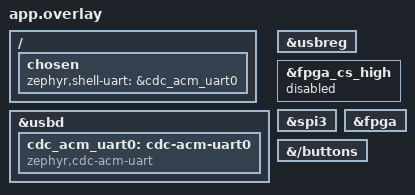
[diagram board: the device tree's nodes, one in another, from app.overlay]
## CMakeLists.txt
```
# SPDX-License-Identifier: Apache-2.0

cmake_minimum_required(VERSION 3.20.0)
list(APPEND BOARD_ROOT "${CMAKE_CURRENT_SOURCE_DIR}/..")
list(APPEND DTS_ROOT "${CMAKE_CURRENT_SOURCE_DIR}/..")
find_package(Zephyr REQUIRED HINTS $ENV{ZEPHYR_BASE})
project(bridge_fpga_dev)

set(VME_FILE "${CMAKE_CURRENT_SOURCE_DIR}/bridge-hello.vme" CACHE FILEPATH "Reviewed Full VME input")
set(VME_HEADER "${CMAKE_CURRENT_BINARY_DIR}/vme_image.h")
add_custom_command(OUTPUT ${VME_HEADER}
  COMMAND ${PYTHON_EXECUTABLE} ${CMAKE_CURRENT_SOURCE_DIR}/tools/embed_vme.py
          ${VME_FILE} ${CMAKE_CURRENT_SOURCE_DIR}/reviewed-vme.sha256 ${VME_HEADER}
  DEPENDS ${VME_FILE} reviewed-vme.sha256 tools/embed_vme.py
  VERBATIM)
target_include_directories(app PRIVATE ${CMAKE_CURRENT_BINARY_DIR})
target_sources(app PRIVATE src/main.c src/vme.c src/jtag.c src/fpga_gpio.c src/fpga_spi.c ${VME_HEADER})
```

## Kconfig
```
mainmenu "Bridge FPGA programmer"

config FPGA_FLASH_WRITE
	bool "Allow explicitly requested FPGA Flash programming"
	default n
	help
	  Enable only after approval of the reviewed VME operation sequence.
	  Programming still requires the explicit USB shell command.

source "Kconfig.zephyr"
```

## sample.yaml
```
sample:
  name: Bridge MachXO2 JTAG programmer
tests:
  sample.bridge.fpga:
    platform_allow: bridge/nrf5340/cpuapp
    integration_platforms:
      - bridge/nrf5340/cpuapp
    build_only: true
    tags:
      - gpio
      - usb
```

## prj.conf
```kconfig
CONFIG_USB_DEVICE_STACK=y
CONFIG_USB_DEVICE_PRODUCT="SenseLab Bridge FPGA Dev"
CONFIG_USB_DEVICE_PID=0x0001
CONFIG_LOG=y
CONFIG_USB_DRIVER_LOG_LEVEL_ERR=y
CONFIG_USB_DEVICE_LOG_LEVEL_ERR=y
CONFIG_SERIAL=y
CONFIG_UART_INTERRUPT_DRIVEN=y
CONFIG_UART_LINE_CTRL=y
CONFIG_USB_DEVICE_INITIALIZE_AT_BOOT=n

# Shared Bridge board GPIOs and FPGA runtime SPI transport.
CONFIG_GPIO=y
CONFIG_GPIO_HOGS=y
CONFIG_SPI=y
CONFIG_TIMING_FUNCTIONS=y
# Use Nordic TIMER2 so elapsed time includes CPU sleep during the SPI wait.
CONFIG_CORTEX_M_DWT=n
CONFIG_SHELL=y
CONFIG_SHELL_BACKEND_SERIAL=y
# Allow pasted shell commands in one USB burst.
CONFIG_SHELL_BACKEND_SERIAL_RX_RING_BUFFER_SIZE=512
CONFIG_SHELL_STACK_SIZE=8192
CONFIG_HEAP_MEM_POOL_SIZE=65536
CONFIG_MAIN_STACK_SIZE=2048
CONFIG_FPGA_FLASH_WRITE=y
```

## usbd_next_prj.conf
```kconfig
CONFIG_USB_DEVICE_STACK_NEXT=y

CONFIG_SERIAL=y
CONFIG_UART_LINE_CTRL=y
CONFIG_USBD_CDC_ACM_CLASS=y

CONFIG_LOG=y
CONFIG_USBD_LOG_LEVEL_WRN=y
CONFIG_UDC_DRIVER_LOG_LEVEL_WRN=y
CONFIG_USBD_CDC_ACM_LOG_LEVEL_ERR=y

CONFIG_SAMPLE_USBD_PID=0x0001
CONFIG_SAMPLE_USBD_PRODUCT="USBD CDC ACM sample"
```

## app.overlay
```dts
/*
 * Copyright (c) 2021 Nordic Semiconductor ASA
 *
 * SPDX-License-Identifier: Apache-2.0
 */

/* Native USB command and diagnostic shell. */
/ {
	chosen { zephyr,shell-uart = &cdc_acm_uart0; };
};
zephyr_udc0: &usbd {
	status = "okay";
	cdc_acm_uart0: cdc-acm-uart0 {
		compatible = "zephyr,cdc-acm-uart";
	};
};

&usbreg { status = "okay"; };

/* SPI3 owns FPGA_CS_N; storage chip selects retain their boot holds. */
&fpga_cs_high { status = "disabled"; };
&spi3 { status = "okay"; };
&fpga { status = "okay"; };

/* Expose BTN_A/BTN_B without input handlers or application actions. */
&{/buttons} { status = "okay"; };
```

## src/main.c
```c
#include <zephyr/kernel.h>
#include <zephyr/drivers/gpio.h>
#include <zephyr/shell/shell.h>
#include <zephyr/usb/usb_device.h>
#include <string.h>
#include "fpga_gpio.h"
#include "jtag.h"
#include "vme_image.h"

static const struct shell *active_shell;
void fpga_message(const char *text)
{
	shell_fprintf(active_shell, SHELL_NORMAL, "%s", text);
}
static int identify(const struct shell *sh)
{
	active_shell = sh;
	int result = fpga_gpio_init();
	uint32_t id = 0;
	if (!result) result = jtag_identify(&fpga_io, &id);
	shell_print(sh, "IDCODE=%08x expected=012b8043 chain-test=%s result=%d DONE=%d",
		    id, result ? "FAIL" : "PASS", result, result ? -1 : fpga_done());
	return result;
}
static int cmd_id(const struct shell *sh, size_t argc, char **argv)
{
	return identify(sh);
}
static int cmd_info(const struct shell *sh, size_t argc, char **argv)
{
	shell_print(sh, "Full VME 12.1, %u bytes, SHA256=%s", (unsigned)sizeof(vme_image), VME_SHA256);
	shell_print(sh, "CRC check=%d; Flash-write support=%s", vme_check(vme_image, sizeof(vme_image)),
		    IS_ENABLED(CONFIG_FPGA_FLASH_WRITE) ? "enabled" : "disabled");
	shell_print(sh, "Sequence includes SRAM/CF/UFM/Feature erase, 575 page writes, USERCODE,");
	shell_print(sh, "Feature Row=0000000000000000, FEABITS=0x0620, verify, DONE and ISC_DISABLE.");
	shell_print(sh, "No OTP/security opcodes. Application behavior is not proven by verification.");
	return 0;
}
static int cmd_program(const struct shell *sh, size_t argc, char **argv)
{
	if (!IS_ENABLED(CONFIG_FPGA_FLASH_WRITE)) {
		shell_error(sh, "Flash writes disabled in this build; first-write approval is required.");
		return -EACCES;
	}
	if (strcmp(argv[1], VME_SHA256)) {
		shell_error(sh, "Supply the full SHA256 printed by fpga info to confirm this exact image.");
		return -EINVAL;
	}
	int result = vme_check(vme_image, sizeof(vme_image));
	if (!result) result = identify(sh);
	if (result) return result;
	shell_print(sh, "Starting approved VME erase/program/verify; do not interrupt power.");
	result = vme_run(vme_image, sizeof(vme_image), &fpga_io);
	shell_print(sh, "Programming %s (%d), DONE=%d. Reboot MCU before another attempt.",
		    result ? "FAILED" : "VERIFIED", result, fpga_done());
	return result;
}
SHELL_STATIC_SUBCMD_SET_CREATE(fpga_commands,
	SHELL_CMD_ARG(info, NULL, "Image and programming scope", cmd_info, 1, 0),
	SHELL_CMD_ARG(id, NULL, "Read-only IDCODE and chain check", cmd_id, 1, 0),
	SHELL_CMD_ARG(program, NULL, "Program reviewed image: <full SHA256>", cmd_program, 2, 0),
	SHELL_SUBCMD_SET_END);
SHELL_CMD_REGISTER(fpga, &fpga_commands, "Bridge FPGA programmer", NULL);

int main(void)
{
	static const struct gpio_dt_spec buttons[] = {
		GPIO_DT_SPEC_GET(DT_ALIAS(sw0), gpios),
		GPIO_DT_SPEC_GET(DT_ALIAS(sw1), gpios),
	};

	/* Apply the DT pull-ups without interrupts, callbacks, or button actions. */
	for (unsigned i = 0; i < ARRAY_SIZE(buttons); i++) {
		int err = gpio_is_ready_dt(&buttons[i]) ?
			gpio_pin_configure_dt(&buttons[i], GPIO_INPUT) : -ENODEV;
		if (err) {
			printk("Button %u input initialization failed: %d\n", i, err);
			return err;
		}
	}
	return usb_enable(NULL);
}
```

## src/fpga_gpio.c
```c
#include "fpga_gpio.h"
#include <zephyr/drivers/gpio.h>
#include <zephyr/kernel.h>

#define FPGA DT_ALIAS(fpga)
static const struct gpio_dt_spec outputs[] = {
	GPIO_DT_SPEC_GET(FPGA, tdi_gpios), GPIO_DT_SPEC_GET(FPGA, tck_gpios),
	GPIO_DT_SPEC_GET(FPGA, tms_gpios),
};
static const struct gpio_dt_spec tdo = GPIO_DT_SPEC_GET(FPGA, tdo_gpios);
static const struct gpio_dt_spec done = GPIO_DT_SPEC_GET(FPGA, done_gpios);
static const struct gpio_dt_spec program = GPIO_DT_SPEC_GET(FPGA, program_gpios);
static const struct gpio_dt_spec inputs[] = {
	GPIO_DT_SPEC_GET(FPGA, irq_gpios),
	GPIO_DT_SPEC_GET_BY_IDX(FPGA, io_gpios, 0),
	GPIO_DT_SPEC_GET_BY_IDX(FPGA, io_gpios, 1),
};

int fpga_gpio_init(void)
{
	for (unsigned i = 0; i < ARRAY_SIZE(outputs); i++) {
		if (!gpio_is_ready_dt(&outputs[i])) return -ENODEV;
		int err = gpio_pin_configure_dt(&outputs[i], i == 1 ? GPIO_OUTPUT_INACTIVE : GPIO_OUTPUT_ACTIVE);
		if (err) return err;
	}
	const struct gpio_dt_spec *pins[] = {&tdo, &done, &program, &inputs[0], &inputs[1], &inputs[2]};
	for (unsigned i = 0; i < ARRAY_SIZE(pins); i++) {
		if (!gpio_is_ready_dt(pins[i])) return -ENODEV;
		int err = gpio_pin_configure_dt(pins[i], pins[i] == &program ? GPIO_OUTPUT_INACTIVE : GPIO_INPUT);
		if (err) return err;
	}
	return 0;
}
static int write_pins(unsigned char mask, unsigned char value)
{
	if (mask & ~7) return -EINVAL;
	for (unsigned i = 0; i < ARRAY_SIZE(outputs); i++) if (mask & BIT(i)) {
		int err = gpio_pin_set_dt(&outputs[i], !!value);
		if (err) return err;
	}
	return 0;
}
static int read_tdo(void) { return gpio_pin_get_dt(&tdo); }
int fpga_done(void) { return gpio_pin_get_dt(&done); }
static void delay_us(uint32_t us)
{
	if (us >= 1000) k_usleep(us);
	else k_busy_wait(us);
}
static uint64_t now_ms(void) { return k_uptime_get(); }
const struct vme_io fpga_io = {write_pins, read_tdo, delay_us, now_ms, fpga_message, NULL};
```

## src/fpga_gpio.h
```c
#ifndef FPGA_GPIO_H
#define FPGA_GPIO_H
#include "vme.h"
int fpga_gpio_init(void);
int fpga_done(void);
extern const struct vme_io fpga_io;
void fpga_message(const char *text);
#endif
```

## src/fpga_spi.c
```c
#include <zephyr/kernel.h>
#include <zephyr/drivers/gpio.h>
#include <zephyr/drivers/pinctrl.h>
#include <zephyr/timing/timing.h>
#include <hal/nrf_spim.h>
#include <string.h>
#include "fpga_spi.h"

/* CONFIG_SPI=n: no Zephyr SPI3 device exists; this module alone owns SPIM3. */
PINCTRL_DT_DEFINE(DT_NODELABEL(spi3));
static NRF_SPIM_Type *const spim = (NRF_SPIM_Type *)DT_REG_ADDR(DT_NODELABEL(spi3));
static const struct gpio_dt_spec cs = GPIO_DT_SPEC_GET_BY_IDX(DT_NODELABEL(spi3), cs_gpios, 0);
/* Persistent DMA storage remains valid even if STOPPED never arrives. */
static uint8_t tx_dma[3] = {0x0f, 0, 0}, rx_dma[3];
static bool ready, faulted;
BUILD_ASSERT(DT_PROP(DT_ALIAS(fpga), spi_max_frequency) == 8000000);

int fpga_spi_init(void)
{
	if (!gpio_is_ready_dt(&cs)) return -ENODEV;
	int err = gpio_pin_configure_dt(&cs, GPIO_OUTPUT_INACTIVE);
	if (err) return err;
	err = pinctrl_apply_state(PINCTRL_DT_DEV_CONFIG_GET(DT_NODELABEL(spi3)), PINCTRL_STATE_DEFAULT);
	if (err) return err;
	nrf_spim_int_disable(spim, UINT32_MAX);
	spim->SHORTS = 0;
	nrf_spim_configure(spim, NRF_SPIM_MODE_0, NRF_SPIM_BIT_ORDER_MSB_FIRST);
	nrf_spim_frequency_set(spim, NRF_SPIM_FREQ_8M);
	ready = true;
	return 0;
}

static bool wait_event(nrf_spim_event_t event)
{
	timing_t start = timing_counter_get();
	while (!nrf_spim_event_check(spim, event)) {
		timing_t now = timing_counter_get();
		if (timing_cycles_get(&start, &now) >= timing_freq_get() / 1000) return false;
	}
	return true;
}

/* Caller owns the shell thread and runs the timing counter during this call. */
int fpga_spi_whoami(uint8_t rx[3])
{
	if (!ready) return -ENODEV;
	if (faulted) return -EIO;
	nrf_spim_event_clear(spim, NRF_SPIM_EVENT_END);
	nrf_spim_event_clear(spim, NRF_SPIM_EVENT_STOPPED);
	nrf_spim_tx_buffer_set(spim, tx_dma, sizeof(tx_dma));
	nrf_spim_rx_buffer_set(spim, rx_dma, sizeof(rx_dma));
	nrf_spim_enable(spim);
	int err = gpio_pin_set_dt(&cs, 1);
	if (!err) {
		k_busy_wait(1);
		__DMB();
		nrf_spim_task_trigger(spim, NRF_SPIM_TASK_START);
		if (!wait_event(NRF_SPIM_EVENT_END)) {
			err = -ETIMEDOUT;
			nrf_spim_task_trigger(spim, NRF_SPIM_TASK_STOP);
			if (!wait_event(NRF_SPIM_EVENT_STOPPED)) {
				/* Do not disable before STOPPED or reuse outstanding DMA. */
				faulted = true;
				err = -EIO;
			}
		} else if (nrf_spim_tx_amount_get(spim) != 3 || nrf_spim_rx_amount_get(spim) != 3) {
			err = -EIO;
		}
		k_busy_wait(1);
	}
	int cs_err = gpio_pin_set_dt(&cs, 0);
	if (!faulted) nrf_spim_disable(spim);
	__DMB();
	if (!err && !cs_err) memcpy(rx, rx_dma, sizeof(rx_dma));
	return err ? err : cs_err;
}
```

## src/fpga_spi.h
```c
#pragma once
#include <stdint.h>

int fpga_spi_init(void);
int fpga_spi_whoami(uint8_t rx[3]);
```

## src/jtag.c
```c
#include "jtag.h"

static int tick(const struct vme_io *io, int tms, int tdi, int *tdo)
{
	if (io->write(VME_TMS, tms) < 0 || io->write(VME_TDI, tdi) < 0) return -1;
	io->delay_us(5);
	int value = io->read();
	if (value < 0) return -1;
	if (tdo) *tdo = value;
	if (io->write(VME_TCK, 1) < 0) return -1;
	io->delay_us(5);
	return io->write(VME_TCK, 0);
}

static int reset(const struct vme_io *io)
{
	if (io->write(VME_TCK, 0) < 0) return -1;
	for (int i = 0; i < 6; i++) if (tick(io, 1, 1, NULL) < 0) return -1;
	return tick(io, 0, 1, NULL);
}
static int enter_shift(const struct vme_io *io, int ir)
{
	if (tick(io, 1, 0, NULL) < 0) return -1;
	if (ir && tick(io, 1, 0, NULL) < 0) return -1;
	if (tick(io, 0, 0, NULL) < 0) return -1;
	return tick(io, 0, 0, NULL);
}
static int finish(const struct vme_io *io)
{
	if (tick(io, 1, 0, NULL) < 0) return -1;
	return tick(io, 0, 0, NULL);
}

int jtag_identify(const struct vme_io *io, uint32_t *id)
{
	uint32_t value = 0;
	int bit;
	if (reset(io) < 0 || enter_shift(io, 0) < 0) return VME_IO_ERROR;
	for (int i = 0; i < 32; i++) {
		if (tick(io, i == 31, 0, &bit) < 0) return VME_IO_ERROR;
		value |= (uint32_t)bit << i;
	}
	*id = value;
	if (finish(io) < 0) return VME_IO_ERROR;
	if (value != 0x012b8043) { reset(io); return VME_POLICY; }
	if (enter_shift(io, 1) < 0) return VME_IO_ERROR;
	unsigned capture = 0;
	for (int i = 0; i < 8; i++) {
		if (tick(io, i == 7, 1, &bit) < 0) return VME_IO_ERROR;
		capture |= (unsigned)bit << i;
	}
	if (finish(io) < 0 || enter_shift(io, 0) < 0) return VME_IO_ERROR;
	/* BYPASS must be exactly one bit, not an extra device or a stuck wire. */
	uint32_t pattern = 0xa5c3695a;
	int previous = 0, bad = (capture & 3) != 1;
	for (int i = 0; i < 64; i++) {
		int input = (pattern >> (i % 32)) & 1;
		if (tick(io, i == 63, input, &bit) < 0) return VME_IO_ERROR;
		bad |= bit != previous;
		previous = input;
	}
	if (finish(io) < 0 || reset(io) < 0) return VME_IO_ERROR;
	return bad ? VME_POLICY : 0;
}
```

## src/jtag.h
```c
#ifndef BRIDGE_JTAG_H
#define BRIDGE_JTAG_H
#include "vme.h"
int jtag_identify(const struct vme_io *io, uint32_t *id);
#endif
```

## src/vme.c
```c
/* Board adapter for Lattice ispVM Embedded. Vendor notices remain in ispvm/. */
#include "vme.h"
#include <limits.h>
#include <setjmp.h>
#include <stdio.h>
#include <stdlib.h>
#include <string.h>
#if defined(__ZEPHYR__) && defined(VME_OFFLINE_AUDIT)
#error "Offline audit is forbidden in firmware"
#endif
#ifdef __ZEPHYR__
#include <zephyr/kernel.h>
#define alloc(n) k_calloc(1, (n))
#define release(p) k_free(p)
#else
#define alloc(n) calloc(1, (n))
#define release(p) free(p)
#endif

static void scan_begin(void);
static void scan_end(int result);
static void fail(int code);
static void compare_failed(unsigned bit, unsigned expected, unsigned actual);
static void poll_exhausted(unsigned attempts);
/* Keep the full interpreter and its TAP/scan/polling algorithms together. */
#pragma push_macro("MAX")
#undef MAX
#include "ispvm/ivm_core.c"
#pragma pop_macro("MAX")

_Static_assert(CHAR_BIT == 8 && sizeof(short) == 2 && sizeof(int) == 4,
	       "ispVM requires 8-bit bytes, 16-bit short, 32-bit int");
/* unsigned long is only used by the vendor checksum accumulator, masked to 16 bits. */

const unsigned char g_ucPinTDI = VME_TDI, g_ucPinTCK = VME_TCK;
const unsigned char g_ucPinTMS = VME_TMS, g_ucPinENABLE = 8;
const unsigned char g_ucPinTRST = 16, g_ucPinTDO = 64;
static const struct vme_io *port;
static const uint8_t *image;
static size_t image_size, cursor;
static jmp_buf escape;
static uint64_t deadline;
static unsigned scans, comparisons;
static unsigned first_bad, expected_bit, actual_bit;
static uint8_t instruction;
static int used;
static struct { void *ptr; size_t size; } buffers[11];

static void fail(int code) { longjmp(escape, -code); }
static void checkpoint(void)
{
	if (port->now_ms() > deadline) fail(VME_TIMEOUT);
}

void writePort(unsigned char pins, unsigned char value)
{
	checkpoint();
	if (pins & ~(VME_TDI | VME_TCK | VME_TMS)) fail(VME_POLICY);
	if (port->write(pins, value) < 0) fail(VME_IO_ERROR);
}

unsigned char readPort(void)
{
	checkpoint();
	int value = port->read();
	if (value < 0 || value > 1) fail(VME_IO_ERROR);
	return (unsigned char)value;
}

void sclock(void)
{
	/* Conservative <=100 kHz, including minimum setup/hold on both phases. */
	port->delay_us(5);
	writePort(g_ucPinTCK, 1);
	port->delay_us(5);
	writePort(g_ucPinTCK, 0);
}

void ispVMDelay(unsigned short delay)
{
	checkpoint();
	port->delay_us((delay & 0x8000) ? (uint32_t)(delay & 0x7fff) * 1000 : delay);
	checkpoint();
}

/* Vendor file comments are informational; keep programming output concise. */
void vme_out_char(unsigned char c) { (void)c; }
void vme_out_hex(unsigned char c) { char s[3]; snprintf(s, sizeof(s), "%02X", c); port->message(s); }
void vme_out_string(char *s) { port->message(s); }

unsigned char GetByte(void)
{
	checkpoint();
	if (g_usDataType & HEAP_IN) {
		if (g_iHeapCounter >= g_iHEAPSize) fail(VME_FILE_READ_FAILURE);
		return g_pucHeapMemory[g_iHeapCounter++];
	}
	if (g_usDataType & LHEAP_IN) {
		if (g_usIntelDataIndex >= g_usIntelBufferSize) fail(VME_FILE_READ_FAILURE);
		return g_pucIntelBuffer[g_usIntelDataIndex++];
	}
	if (cursor >= image_size) fail(VME_FILE_READ_FAILURE);
	return image[cursor++];
}

static void *buffer(unsigned slot, size_t size)
{
	if (size > 65537) fail(VME_MEMORY);
	if (buffers[slot].size < size) {
		void *p = alloc(size);
		if (!p) fail(VME_MEMORY);
		if (buffers[slot].ptr) memcpy(p, buffers[slot].ptr, buffers[slot].size);
		release(buffers[slot].ptr);
		buffers[slot].ptr = p;
		buffers[slot].size = size;
	}
	return buffers[slot].ptr;
}

void ispVMMemManager(signed char target, unsigned short size)
{
	size_t bytes = (size_t)size / 8 + 2;
	switch (target) {
	case XTDI: case TDI:
		g_pucInData = buffer(0, bytes);
		/* Vendor TDI allocation also provisions the next expected-data buffer. */
		g_pucOutData = buffer(1, bytes); break;
	case XTDO: case TDO: g_pucOutData = buffer(1, bytes); break;
	case MASK: g_pucOutMaskData = buffer(2, bytes); break;
	case DMASK: g_pucOutDMaskData = buffer(3, bytes); break;
	case HIR: g_pucHIRData = buffer(4, bytes); break;
	case TIR: g_pucTIRData = buffer(5, bytes); break;
	case HDR: g_pucHDRData = buffer(6, bytes); break;
	case TDR: g_pucTDRData = buffer(7, bytes); break;
	case HEAP: g_pucHeapMemory = buffer(8, (size_t)size + 2); break;
	case LHEAP: g_pucIntelBuffer = buffer(9, (size_t)size + 2); break;
	case LVDS: g_pLVDSList = buffer(10, (size_t)size * sizeof(LVDSPair)); break;
	default: break; /* Vendor calls this for non-allocation data tokens too. */
	}
}

static uint8_t reverse8(uint8_t value)
{
	uint8_t out = 0;
	for (int i = 0; i < 8; i++) { out = (out << 1) | (value & 1); value >>= 1; }
	return out;
}

static void scan_begin(void)
{
	char line[96];
	first_bad = UINT_MAX;
	if (!g_usiDataSize || g_usiDataSize > SCANMAX ||
	    (g_usFlowControl & VERIFYUES) || (g_usDataType & (CMASK_DATA | DMASK_DATA)))
		fail(VME_POLICY);
	if (g_usDataType & SIR_DATA) {
		if (g_usiDataSize != 8 || !(g_usDataType & TDI_DATA)) fail(VME_POLICY);
		instruction = reverse8(g_pucInData[0]);
		/* Security/OTP/feature programming are never silently admitted. */
		switch (instruction) {
		case 0xe0: case 0x1c: case 0x3c: case 0xc6: case 0x0e:
		case 0xff: case 0xf0: case 0x46: case 0x70: case 0x73:
		case 0x5e: case 0x26: case 0xc0: case 0xc2:
		case 0xe4: case 0xe7: case 0xf8: case 0xfb:
			break;
		default:
#ifndef VME_OFFLINE_AUDIT
			snprintf(line, sizeof(line), "Blocked unreviewed JTAG instruction 0x%02x\n", instruction);
			port->message(line); fail(VME_POLICY);
#endif
			break;
		}
	}
	/* Match reviewed erase/feature payloads; never broaden an erase target. */
	if (g_usDataType & SDR_DATA) {
		const uint8_t *d = g_pucInData;
		if (!(g_usDataType & TDI_DATA)) fail(VME_POLICY);
		if (instruction == 0x0e && (g_usiDataSize != 8 ||
		    (reverse8(d[0]) != 1 && reverse8(d[0]) != 14))) fail(VME_POLICY);
		if (instruction == 0xe4 && (g_usiDataSize != 64 ||
		    memcmp(d, (uint8_t[8]){0}, 8))) fail(VME_POLICY);
		if (instruction == 0xf8 && (g_usiDataSize != 16 ||
		    reverse8(d[0]) != 0x20 || reverse8(d[1]) != 0x06)) fail(VME_POLICY);
	}
	++scans;
	if (g_usDataType & TDO_DATA) ++comparisons;
	if (port->scan) port->scan(!!(g_usDataType & SIR_DATA), g_usiDataSize,
		g_usDataType & TDI_DATA ? g_pucInData : NULL,
		g_usDataType & TDO_DATA ? g_pucOutData : NULL,
		g_usDataType & MASK_DATA ? g_pucOutMaskData : NULL);
}

static void scan_end(int result)
{
	/* A busy response inside the VME polling loop is expected; exhaustion
	 * remains an error reported by poll_exhausted(). */
	if (result < 0 && !(instruction == 0xf0 && (g_usDataType & LHEAP_IN))) {
		char line[160];
		snprintf(line, sizeof(line), "TDO mismatch scan=%u IR=%02x bits=%u first-bit=%u expected=%u actual=%u%s\n",
			 scans, instruction, g_usiDataSize, first_bad, expected_bit, actual_bit,
			 g_usDataType & LHEAP_IN ? " (poll may retry)" : "");
		port->message(line);
	}
}

static void compare_failed(unsigned bit, unsigned expected, unsigned actual)
{
	if (first_bad == UINT_MAX) {
		first_bad = bit; expected_bit = expected; actual_bit = actual;
	}
}

static void poll_exhausted(unsigned attempts)
{
	char line[80];
	snprintf(line, sizeof(line), "Polling retry limit exhausted: %u attempts, IR=%02x\n", attempts, instruction);
	port->message(line);
}

int vme_check(const uint8_t *data, size_t size)
{
	if (size < 13 || data[0] != FILE_CRC) return VME_INVALID_FILE;
	if (memcmp(data + 3, "____12.1", 8)) return VME_VERSION_FAILURE;
	if (data[11] != 0xf2) return VME_POLICY; /* Reviewed uncompressed Full VME. */
	g_usCalculatedCRC = 0;
	for (size_t i = 3; i < size; ++i) ispVMCalculateCRC32(data[i]);
	if (g_usCalculatedCRC != ((unsigned)data[1] << 8 | data[2])) return VME_CRC_FAILURE;
	return 0;
}

int vme_run(const uint8_t *data, size_t size, const struct vme_io *io)
{
	int result = vme_check(data, size);
	if (result) return result;
	if (used) return VME_ALREADY_RUN;
	used = 1;
	port = io; image = data; image_size = size; cursor = 11;
	deadline = port->now_ms() + 180000;
	int trapped = setjmp(escape);
	if (!trapped) {
		ispVMStart();
		result = ispVMCode();
		if (result == 0 && (cursor != size || !comparisons)) result = VME_INVALID_FILE;
		ispVMEnd();
	} else {
		result = -trapped;
		/* Do not issue cleanup programming commands after a failure. */
		port->write(VME_TCK, 0);
		port->write(VME_TMS | VME_TDI, 1);
	}
	for (unsigned i = 0; i < 11; i++) release(buffers[i].ptr);
	if (result) {
		char line[96];
		snprintf(line, sizeof(line), "VME failed: result=%d scan=%u file=%u/%u IR=%02x\n",
			 result, scans, (unsigned)cursor, (unsigned)image_size, instruction);
		port->message(line);
	}
	return result;
}
```

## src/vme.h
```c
#ifndef BRIDGE_VME_H
#define BRIDGE_VME_H

#include <stddef.h>
#include <stdint.h>

/* Single-threaded, one programming attempt per boot. No automatic retry. */
struct vme_io {
	int (*write)(unsigned char pins, unsigned char value);
	int (*read)(void);
	void (*delay_us)(uint32_t us);
	uint64_t (*now_ms)(void);
	void (*message)(const char *text);
	/* Optional trace observer, used by host tests; never substitutes real TDO. */
	void (*scan)(int ir, unsigned bits, const uint8_t *tdi,
		     const uint8_t *tdo, const uint8_t *mask);
};

enum { VME_TDI = 1, VME_TCK = 2, VME_TMS = 4 };
enum { VME_IO_ERROR = -20, VME_TIMEOUT = -21, VME_MEMORY = -22,
	VME_POLICY = -23, VME_ALREADY_RUN = -24 };

int vme_check(const uint8_t *data, size_t size);
int vme_run(const uint8_t *data, size_t size, const struct vme_io *io);

#endif
```
